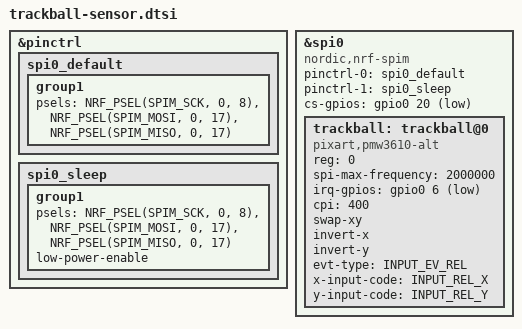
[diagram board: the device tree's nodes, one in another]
/*
 * PMW3610 trackball on SPI0 — physically wired to the right half.
 * Shared by charybdis_right (bluetooth central, local sensor) and
 * charybdis_right_dongle (dongle-mode peripheral, forwarded sensor).
 *
 * Uses the badjeff "-alt" driver: it emits raw relative motion; auto-mouse /
 * scroll / snipe live on the central as native ZMK input-processors
 * (see trackball-input.dtsi), not as driver-side layer properties.
 */

#include <zephyr/dt-bindings/input/input-event-codes.h>

&pinctrl {
    spi0_default: spi0_default {
        group1 {
            psels = <NRF_PSEL(SPIM_SCK, 0, 8)>,
                <NRF_PSEL(SPIM_MOSI, 0, 17)>,
                <NRF_PSEL(SPIM_MISO, 0, 17)>;
        };
    };

    spi0_sleep: spi0_sleep {
        group1 {
            psels = <NRF_PSEL(SPIM_SCK, 0, 8)>,
                <NRF_PSEL(SPIM_MOSI, 0, 17)>,
                <NRF_PSEL(SPIM_MISO, 0, 17)>;
            low-power-enable;
        };
    };
};

&spi0 {
    status = "okay";
    compatible = "nordic,nrf-spim";
    pinctrl-0 = <&spi0_default>;
    pinctrl-1 = <&spi0_sleep>;
    pinctrl-names = "default", "sleep";
    cs-gpios = <&gpio0 20 GPIO_ACTIVE_LOW>;

    trackball: trackball@0 {
        status = "okay";
        compatible = "pixart,pmw3610-alt";
        reg = <0>;
        spi-max-frequency = <2000000>;
        irq-gpios = <&gpio0 6 (GPIO_ACTIVE_LOW | GPIO_PULL_UP)>;

        cpi = <400>;
        // Orientation: replaces the old CONFIG_PMW3610_ORIENTATION_90 +
        // CONFIG_PMW3610_INVERT_X. Tweak swap-xy / invert-x / invert-y if the
        // cursor moves along the wrong axis or in the wrong direction.
        // invert-y: pulling the ball down was moving the cursor up. This flips
        // Y for everything downstream, so the scroll layer drops its own
        // Y_INVERT to compensate (see trackball-input.dtsi).
        swap-xy;
        invert-x;
        invert-y;

        evt-type = <INPUT_EV_REL>;
        x-input-code = <INPUT_REL_X>;
        y-input-code = <INPUT_REL_Y>;
    };
};
